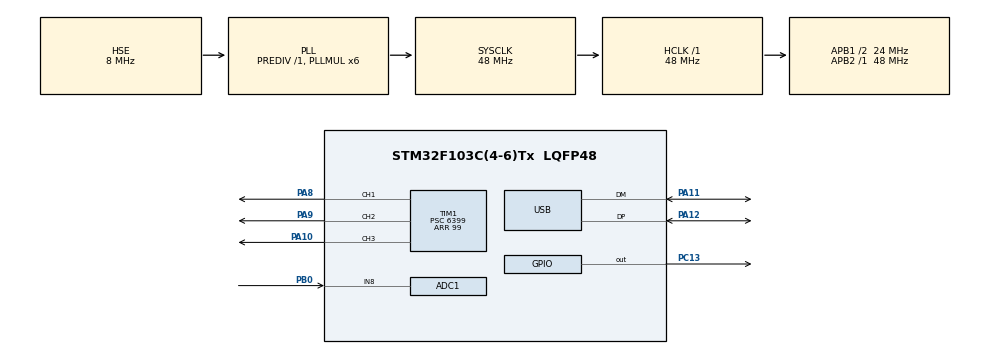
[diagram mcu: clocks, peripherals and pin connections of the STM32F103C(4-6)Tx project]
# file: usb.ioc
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Mcu.Family=STM32F1
USB_DEVICE.CLASS_NAME_FS=CDC
ADC1.Rank-0\#ChannelRegularConversion=1
PD1-OSC_OUT.Mode=HSE-External-Oscillator
USB_DEVICE.VirtualModeFS=Cdc_FS
USB_DEVICE.INTERFACE_STRING_CDC_FS=RR Interface
PC13-TAMPER-RTC.Signal=GPIO_Output
PA11.Mode=Device
PD0-OSC_IN.Signal=RCC_OSC_IN
TIM1.Pulse-PWM\ Generation1\ CH1=50
RCC.APB1CLKDivider=RCC_HCLK_DIV2
RCC.SYSCLKSource=RCC_SYSCLKSOURCE_PLLCLK
ProjectManager.StackSize=0x400
PD1-OSC_OUT.Signal=RCC_OSC_OUT
RCC.ADCPresc=RCC_ADCPCLK2_DIV4
PA13.Signal=SYS_JTMS-SWDIO
TIM1.Pulse-PWM\ Generation3\ CH3=50
USB_DEVICE.MANUFACTURER_STRING=RedRock
PA12.Signal=USB_DP
TIM1.Prescaler=6399
SH.S_TIM1_CH1.0=TIM1_CH1,PWM Generation1 CH1
ProjectManager.TargetToolchain=MDK-ARM V5.27
USB_DEVICE.PRODUCT_STRING_CDC_FS=RR-001
RCC.HCLKFreq_Value=48000000
VP_USB_DEVICE_VS_USB_DEVICE_CDC_FS.Mode=CDC_FS
RCC.APB2TimFreq_Value=48000000
PA9.Signal=S_TIM1_CH2
TIM1.Channel-PWM\ Generation2\ CH2=TIM_CHANNEL_2
USB_DEVICE.CONFIGURATION_STRING_CDC_FS=RR Config
RCC.USBFreq_Value=48000000
RCC.AHBFreq_Value=48000000
PD0-OSC_IN.Mode=HSE-External-Oscillator
ADC1.Channel-0\#ChannelRegularConversion=ADC_CHANNEL_8
board=custom
RCC.PLLMUL=RCC_PLL_MUL6
RCC.APB2Freq_Value=48000000
SH.S_TIM1_CH2.0=TIM1_CH2,PWM Generation2 CH2
TIM1.Channel-PWM\ Generation1\ CH1=TIM_CHANNEL_1
PA14.Mode=Serial_Wire
NVIC.USB_LP_CAN1_RX0_IRQn=true\:0\:0\:false\:false\:true\:false\:true
SH.ADCx_IN8.0=ADC1_IN8,IN8
PA8.Signal=S_TIM1_CH1
PA13.Mode=Serial_Wire
Mcu.Name=STM32F103C(4-6)Tx
ADC1.SamplingTime-0\#ChannelRegularConversion=ADC_SAMPLETIME_1CYCLE_5
RCC.SYSCLKFreq_VALUE=48000000
Mcu.Package=LQFP48
ADC1.master=1
PA12.Mode=Device
TIM1.Pulse-PWM\ Generation2\ CH2=50
PA11.Signal=USB_DM
PA10.Signal=S_TIM1_CH3
PA14.Signal=SYS_JTCK-SWCLK
ProjectManager.HeapSize=0x200
SH.S_TIM1_CH3.0=TIM1_CH3,PWM Generation3 CH3
NVIC.PriorityGroup=NVIC_PRIORITYGROUP_4
ADC1.NbrOfConversionFlag=1
RCC.APB1TimFreq_Value=48000000
TIM1.Period=99
TIM1.Channel-PWM\ Generation3\ CH3=TIM_CHANNEL_3
RCC.APB1Freq_Value=24000000
PB0.Signal=ADCx_IN8
USB_DEVICE.VirtualMode=Cdc

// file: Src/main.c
/* USER CODE BEGIN Header */
/**
  ******************************************************************************
  * @file           : main.c
  * @brief          : Main program body
  ******************************************************************************
  * @attention
  *
  * <h2><center>&copy; Copyright (c) 2020 STMicroelectronics.
  * All rights reserved.</center></h2>
  *
  * This software component is licensed by ST under Ultimate Liberty license
  * SLA0044, the "License"; You may not use this file except in compliance with
  * the License. You may obtain a copy of the License at:
  *                             www.st.com/SLA0044
  *
  ******************************************************************************
  */
/* USER CODE END Header */

#include "main.h"
#include "usb_device.h"

ADC_HandleTypeDef hadc1;

TIM_HandleTypeDef htim1;

void SystemClock_Config(void);
static void MX_GPIO_Init(void);
static void MX_ADC1_Init(void);
static void MX_TIM1_Init(void);

int main(void)
{

  /* MCU Configuration--------------------------------------------------------*/

  /* Reset of all peripherals, Initializes the Flash interface and the Systick. */
  HAL_Init();

  /* Configure the system clock */
  SystemClock_Config();

  /* Initialize all configured peripherals */
  MX_GPIO_Init();
  MX_USB_DEVICE_Init();
  MX_ADC1_Init();
  MX_TIM1_Init();

  /* USER CODE BEGIN 2 */
	HAL_TIM_PWM_Start(&htim1,TIM_CHANNEL_1);
	HAL_TIM_PWM_Start(&htim1,TIM_CHANNEL_2);
	HAL_TIM_PWM_Start(&htim1,TIM_CHANNEL_3);

	__HAL_TIM_SET_COMPARE(&htim1,TIM_CHANNEL_1,0);
	__HAL_TIM_SET_COMPARE(&htim1,TIM_CHANNEL_2,0);
	__HAL_TIM_SET_COMPARE(&htim1,TIM_CHANNEL_3,0);

	uint8_t hi[15]="HelloWorld\n ";
  /* USER CODE END 2 */

  /* Infinite loop */
  while (1)
  {

    /* USER CODE BEGIN 3 */
		/*
		CDC_Transmit_FS(hi, 12);
		HAL_Delay(1000);*/
	//	appStart();

  }
  /* USER CODE END 3 */
}

void SystemClock_Config(void)
{
  RCC_OscInitTypeDef RCC_OscInitStruct = {0};
  RCC_ClkInitTypeDef RCC_ClkInitStruct = {0};
  RCC_PeriphCLKInitTypeDef PeriphClkInit = {0};

  /** Initializes the CPU, AHB and APB busses clocks
  */
  RCC_OscInitStruct.OscillatorType = RCC_OSCILLATORTYPE_HSE;
  RCC_OscInitStruct.HSEState = RCC_HSE_ON;
  RCC_OscInitStruct.HSEPredivValue = RCC_HSE_PREDIV_DIV1;
  RCC_OscInitStruct.HSIState = RCC_HSI_ON;
  RCC_OscInitStruct.PLL.PLLState = RCC_PLL_ON;
  RCC_OscInitStruct.PLL.PLLSource = RCC_PLLSOURCE_HSE;
  RCC_OscInitStruct.PLL.PLLMUL = RCC_PLL_MUL6;
  if (HAL_RCC_OscConfig(&RCC_OscInitStruct) != HAL_OK)
  {
    Error_Handler();
  }
  /** Initializes the CPU, AHB and APB busses clocks
  */
  RCC_ClkInitStruct.ClockType = RCC_CLOCKTYPE_HCLK|RCC_CLOCKTYPE_SYSCLK
                              |RCC_CLOCKTYPE_PCLK1|RCC_CLOCKTYPE_PCLK2;
  RCC_ClkInitStruct.SYSCLKSource = RCC_SYSCLKSOURCE_PLLCLK;
  RCC_ClkInitStruct.AHBCLKDivider = RCC_SYSCLK_DIV1;
  RCC_ClkInitStruct.APB1CLKDivider = RCC_HCLK_DIV2;
  RCC_ClkInitStruct.APB2CLKDivider = RCC_HCLK_DIV1;

  if (HAL_RCC_ClockConfig(&RCC_ClkInitStruct, FLASH_LATENCY_1) != HAL_OK)
  {
    Error_Handler();
  }
  PeriphClkInit.PeriphClockSelection = RCC_PERIPHCLK_ADC|RCC_PERIPHCLK_USB;
  PeriphClkInit.AdcClockSelection = RCC_ADCPCLK2_DIV4;
  PeriphClkInit.UsbClockSelection = RCC_USBCLKSOURCE_PLL;
  if (HAL_RCCEx_PeriphCLKConfig(&PeriphClkInit) != HAL_OK)
  {
    Error_Handler();
  }
}

static void MX_ADC1_Init(void)
{

  ADC_ChannelConfTypeDef sConfig = {0};

  /** Common config
  */
  hadc1.Instance = ADC1;
  hadc1.Init.ScanConvMode = ADC_SCAN_DISABLE;
  hadc1.Init.ContinuousConvMode = DISABLE;
  hadc1.Init.DiscontinuousConvMode = DISABLE;
  hadc1.Init.ExternalTrigConv = ADC_SOFTWARE_START;
  hadc1.Init.DataAlign = ADC_DATAALIGN_RIGHT;
  hadc1.Init.NbrOfConversion = 1;
  if (HAL_ADC_Init(&hadc1) != HAL_OK)
  {
    Error_Handler();
  }
  /** Configure Regular Channel
  */
  sConfig.Channel = ADC_CHANNEL_8;
  sConfig.Rank = ADC_REGULAR_RANK_1;
  sConfig.SamplingTime = ADC_SAMPLETIME_1CYCLE_5;
  if (HAL_ADC_ConfigChannel(&hadc1, &sConfig) != HAL_OK)
  {
    Error_Handler();
  }

}

static void MX_TIM1_Init(void)
{

  TIM_MasterConfigTypeDef sMasterConfig = {0};
  TIM_OC_InitTypeDef sConfigOC = {0};
  TIM_BreakDeadTimeConfigTypeDef sBreakDeadTimeConfig = {0};

  htim1.Instance = TIM1;
  htim1.Init.Prescaler = 6399;
  htim1.Init.CounterMode = TIM_COUNTERMODE_UP;
  htim1.Init.Period = 99;
  htim1.Init.ClockDivision = TIM_CLOCKDIVISION_DIV1;
  htim1.Init.RepetitionCounter = 0;
  htim1.Init.AutoReloadPreload = TIM_AUTORELOAD_PRELOAD_DISABLE;
  if (HAL_TIM_PWM_Init(&htim1) != HAL_OK)
  {
    Error_Handler();
  }
  sMasterConfig.MasterOutputTrigger = TIM_TRGO_RESET;
  sMasterConfig.MasterSlaveMode = TIM_MASTERSLAVEMODE_DISABLE;
  if (HAL_TIMEx_MasterConfigSynchronization(&htim1, &sMasterConfig) != HAL_OK)
  {
    Error_Handler();
  }
  sConfigOC.OCMode = TIM_OCMODE_PWM1;
  sConfigOC.Pulse = 50;
  sConfigOC.OCPolarity = TIM_OCPOLARITY_HIGH;
  sConfigOC.OCNPolarity = TIM_OCNPOLARITY_HIGH;
  sConfigOC.OCFastMode = TIM_OCFAST_DISABLE;
  sConfigOC.OCIdleState = TIM_OCIDLESTATE_RESET;
  sConfigOC.OCNIdleState = TIM_OCNIDLESTATE_RESET;
  if (HAL_TIM_PWM_ConfigChannel(&htim1, &sConfigOC, TIM_CHANNEL_1) != HAL_OK)
  {
    Error_Handler();
  }
  if (HAL_TIM_PWM_ConfigChannel(&htim1, &sConfigOC, TIM_CHANNEL_2) != HAL_OK)
  {
    Error_Handler();
  }
  if (HAL_TIM_PWM_ConfigChannel(&htim1, &sConfigOC, TIM_CHANNEL_3) != HAL_OK)
  {
    Error_Handler();
  }
  sBreakDeadTimeConfig.OffStateRunMode = TIM_OSSR_DISABLE;
  sBreakDeadTimeConfig.OffStateIDLEMode = TIM_OSSI_DISABLE;
  sBreakDeadTimeConfig.LockLevel = TIM_LOCKLEVEL_OFF;
  sBreakDeadTimeConfig.DeadTime = 0;
  sBreakDeadTimeConfig.BreakState = TIM_BREAK_DISABLE;
  sBreakDeadTimeConfig.BreakPolarity = TIM_BREAKPOLARITY_HIGH;
  sBreakDeadTimeConfig.AutomaticOutput = TIM_AUTOMATICOUTPUT_DISABLE;
  if (HAL_TIMEx_ConfigBreakDeadTime(&htim1, &sBreakDeadTimeConfig) != HAL_OK)
  {
    Error_Handler();
  }
  HAL_TIM_MspPostInit(&htim1);

}

static void MX_GPIO_Init(void)
{
  GPIO_InitTypeDef GPIO_InitStruct = {0};

  /* GPIO Ports Clock Enable */
  __HAL_RCC_GPIOC_CLK_ENABLE();
  __HAL_RCC_GPIOD_CLK_ENABLE();
  __HAL_RCC_GPIOB_CLK_ENABLE();
  __HAL_RCC_GPIOA_CLK_ENABLE();

  /*Configure GPIO pin Output Level */
  HAL_GPIO_WritePin(GPIOC, GPIO_PIN_13, GPIO_PIN_RESET);

  /*Configure GPIO pin : PC13 */
  GPIO_InitStruct.Pin = GPIO_PIN_13;
  GPIO_InitStruct.Mode = GPIO_MODE_OUTPUT_PP;
  GPIO_InitStruct.Pull = GPIO_NOPULL;
  GPIO_InitStruct.Speed = GPIO_SPEED_FREQ_LOW;
  HAL_GPIO_Init(GPIOC, &GPIO_InitStruct);

}

void Error_Handler(void)
{
}

/************************ (C) COPYRIGHT STMicroelectronics *****END OF FILE****/
